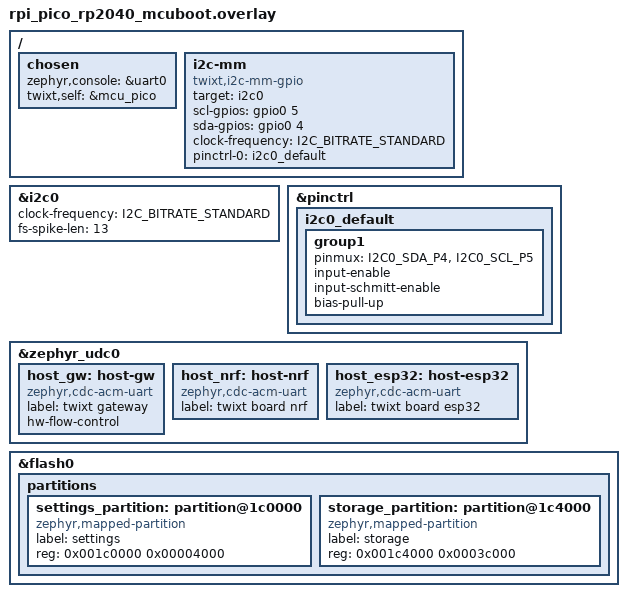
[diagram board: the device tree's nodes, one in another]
/*
 * Copyright (c) 2026 Christoph Jans
 * SPDX-License-Identifier: Apache-2.0
 */

/* The bus: SDA GP4 (pin 6), SCL GP5 (pin 7), at 3.3 V. I2C0 is only the target, since the
 * DesignWare block cannot be controller and target at once; the controller is software on the
 * same pins (twixt,i2c-mm-gpio), and pinctrl-0 gives the pins back to I2C0. The ports to the
 * laptop are USB CDC-ACM (src/usb.c), the gateway first; the log is on UART0 (GP0).
 */

#include <zephyr/dt-bindings/i2c/i2c.h>



/ {
	chosen {
		zephyr,console = &uart0;
		twixt,self = &mcu_pico;
	};

	i2c-mm {
		compatible = "twixt,i2c-mm-gpio";
		target = <&i2c0>;
		scl-gpios = <&gpio0 5 0>;
		sda-gpios = <&gpio0 4 0>;
		clock-frequency = <I2C_BITRATE_STANDARD>;
		pinctrl-0 = <&i2c0_default>;
		pinctrl-names = "default";
		#address-cells = <1>;
		#size-cells = <0>;

#include "../twixt_hardware_mcus.dtsi"
	};
};

&i2c0 {
	clock-frequency = <I2C_BITRATE_STANDARD>;
	fs-spike-len = <13>; /* 104 ns at 125 MHz */
};

&pinctrl {
	i2c0_default: i2c0_default {
		group1 {
			pinmux = <I2C0_SDA_P4>, <I2C0_SCL_P5>;
			input-enable;
			input-schmitt-enable;
			bias-pull-up; /* weak; the bus needs its own pull-ups */
		};
	};
};

&zephyr_udc0 {
	host_gw: host-gw {
		compatible = "zephyr,cdc-acm-uart";
		label = "twixt gateway";
		/* MCUmgr writes its responses with poll_out: wait instead of dropping */
		hw-flow-control;
	};


	host_nrf: host-nrf {
		compatible = "zephyr,cdc-acm-uart";
		label = "twixt board nrf";
	};

	host_esp32: host-esp32 {
		compatible = "zephyr,cdc-acm-uart";
		label = "twixt board esp32";
	};
};

/delete-node/ &storage_partition;
&flash0 {
  partitions {
    settings_partition: partition@1c0000 {
      compatible = "zephyr,mapped-partition";
      label = "settings";
      reg = <0x001c0000 0x00004000>;
    };
    storage_partition: partition@1c4000 {
      compatible = "zephyr,mapped-partition";
      label = "storage";
      reg = <0x001c4000 0x0003c000>;
    };
  };
};
